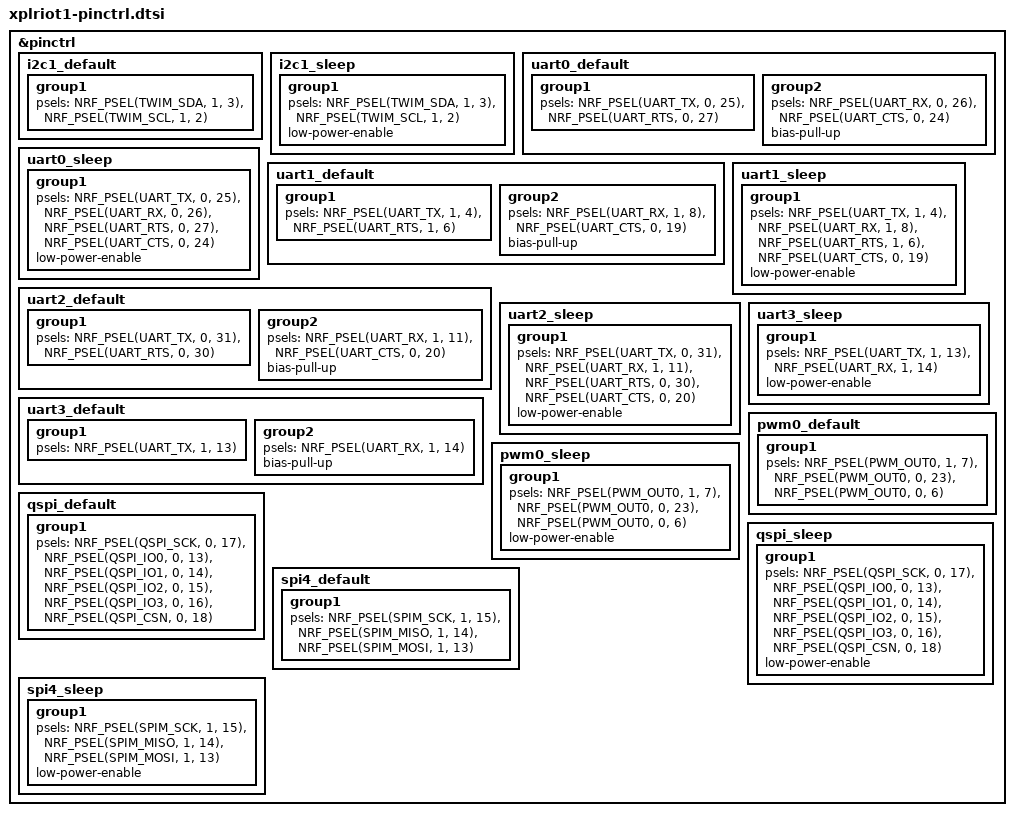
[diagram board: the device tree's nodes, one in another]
/*
 * Copyright (c) 2022 u-blox
 * SPDX-License-Identifier: Apache-2.0
 */

&pinctrl {
	i2c1_default: i2c1_default {
		group1 {
			psels = <NRF_PSEL(TWIM_SDA, 1, 3)>,
							<NRF_PSEL(TWIM_SCL, 1, 2)>;
		};
	};

	i2c1_sleep: i2c1_sleep {
		group1 {
			psels = <NRF_PSEL(TWIM_SDA, 1, 3)>,
							<NRF_PSEL(TWIM_SCL, 1, 2)>;
			low-power-enable;
		};
	};

	uart0_default: uart0_default {
		group1 {
			psels = <NRF_PSEL(UART_TX, 0, 25)>,
							<NRF_PSEL(UART_RTS, 0, 27)>;
		};
		group2 {
			psels = <NRF_PSEL(UART_RX, 0, 26)>,
							<NRF_PSEL(UART_CTS, 0, 24)>;
			bias-pull-up;
		};
	};

	uart0_sleep: uart0_sleep {
		group1 {
			psels = <NRF_PSEL(UART_TX, 0, 25)>,
			        <NRF_PSEL(UART_RX, 0, 26)>,
			        <NRF_PSEL(UART_RTS, 0, 27)>,
			        <NRF_PSEL(UART_CTS, 0, 24)>;
			low-power-enable;
		};
	};

	uart1_default: uart1_default {
		group1 {
			psels = <NRF_PSEL(UART_TX, 1, 4)>,
							<NRF_PSEL(UART_RTS, 1, 6)>;
		};
		group2 {
			psels = <NRF_PSEL(UART_RX, 1, 8)>,
							<NRF_PSEL(UART_CTS, 0, 19)>;
			bias-pull-up;
		};
	};

	uart1_sleep: uart1_sleep {
		group1 {
			psels = <NRF_PSEL(UART_TX, 1, 4)>,
			        <NRF_PSEL(UART_RX, 1, 8)>,
			        <NRF_PSEL(UART_RTS, 1, 6)>,
			        <NRF_PSEL(UART_CTS, 0, 19)>;
			low-power-enable;
		};
	};

	uart2_default: uart2_default {
		group1 {
			psels = <NRF_PSEL(UART_TX, 0, 31)>,
							<NRF_PSEL(UART_RTS, 0, 30)>;
		};
		group2 {
			psels = <NRF_PSEL(UART_RX, 1, 11)>,
							<NRF_PSEL(UART_CTS, 0, 20)>;
			bias-pull-up;
		};
	};

	uart2_sleep: uart2_sleep {
		group1 {
			psels = <NRF_PSEL(UART_TX, 0, 31)>,
			        <NRF_PSEL(UART_RX, 1, 11)>,
			        <NRF_PSEL(UART_RTS, 0, 30)>,
			        <NRF_PSEL(UART_CTS, 0, 20)>;
			low-power-enable;
		};
	};

	uart3_default: uart3_default {
		group1 {
			psels = <NRF_PSEL(UART_TX, 1, 13)>;
		};
		group2 {
			psels = <NRF_PSEL(UART_RX, 1, 14)>;
			bias-pull-up;
		};
	};

	uart3_sleep: uart3_sleep {
		group1 {
			psels = <NRF_PSEL(UART_TX, 1, 13)>,
			        <NRF_PSEL(UART_RX, 1, 14)>;
			low-power-enable;
		};
	};

	pwm0_default: pwm0_default {
		group1 {
			psels = <NRF_PSEL(PWM_OUT0, 1, 7)>,
			        <NRF_PSEL(PWM_OUT0, 0, 23)>,
			        <NRF_PSEL(PWM_OUT0, 0, 6)>;
		};
	};

	pwm0_sleep: pwm0_sleep {
		group1 {
			psels = <NRF_PSEL(PWM_OUT0, 1, 7)>,
			        <NRF_PSEL(PWM_OUT0, 0, 23)>,
			        <NRF_PSEL(PWM_OUT0, 0, 6)>;
			low-power-enable;
		};
	};

	qspi_default: qspi_default {
		group1 {
			psels = <NRF_PSEL(QSPI_SCK, 0, 17)>,
			        <NRF_PSEL(QSPI_IO0, 0, 13)>,
			        <NRF_PSEL(QSPI_IO1, 0, 14)>,
			        <NRF_PSEL(QSPI_IO2, 0, 15)>,
			        <NRF_PSEL(QSPI_IO3, 0, 16)>,
			        <NRF_PSEL(QSPI_CSN, 0, 18)>;
		};
	};

	qspi_sleep: qspi_sleep {
		group1 {
			psels = <NRF_PSEL(QSPI_SCK, 0, 17)>,
			        <NRF_PSEL(QSPI_IO0, 0, 13)>,
			        <NRF_PSEL(QSPI_IO1, 0, 14)>,
			        <NRF_PSEL(QSPI_IO2, 0, 15)>,
			        <NRF_PSEL(QSPI_IO3, 0, 16)>,
			        <NRF_PSEL(QSPI_CSN, 0, 18)>;
			low-power-enable;
		};
	};

	spi4_default: spi4_default {
		group1 {
			psels = <NRF_PSEL(SPIM_SCK, 1, 15)>,
			        <NRF_PSEL(SPIM_MISO, 1, 14)>,
			        <NRF_PSEL(SPIM_MOSI, 1, 13)>;
		};
	};

	spi4_sleep: spi4_sleep {
		group1 {
			psels = <NRF_PSEL(SPIM_SCK, 1, 15)>,
			        <NRF_PSEL(SPIM_MISO, 1, 14)>,
			        <NRF_PSEL(SPIM_MOSI, 1, 13)>;
			low-power-enable;
		};
	};

};
